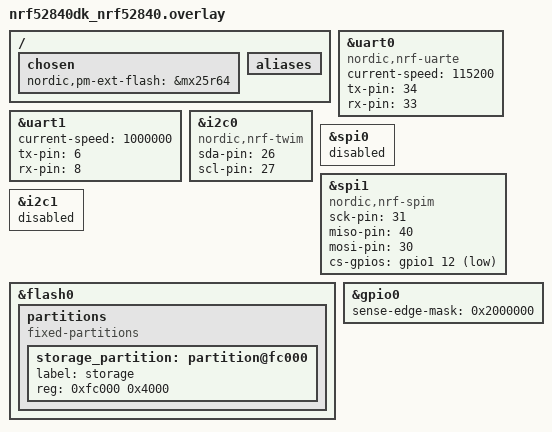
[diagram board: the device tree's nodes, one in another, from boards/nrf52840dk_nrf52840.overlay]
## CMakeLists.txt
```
# SPDX-License-Identifier: Apache-2.0

cmake_minimum_required(VERSION 3.13.1)

find_package(Zephyr REQUIRED HINTS $ENV{ZEPHYR_BASE})
project(comprensive_example)

# NORDIC SDK APP START

target_sources(app PRIVATE src/main.c)

target_sources_ifdef(CONFIG_EXAMPLE_I2C app
                     PRIVATE src/iic_thread.c)
					 
target_sources_ifdef(CONFIG_EXAMPLE_SPIM app
                     PRIVATE src/spi_thread.c)
					 
target_sources_ifdef(CONFIG_EXAMPLE_HS_UART app
                     PRIVATE src/uart_thread.c)
					 
target_sources_ifdef(CONFIG_EXAMPLE_ADC app
                     PRIVATE src/adc_thread.c)
					 
target_sources_ifdef(CONFIG_EXAMPLE_FLASH app
                     PRIVATE src/flash_thread.c)

zephyr_library_include_directories(.)

# NORDIC SDK APP END
```

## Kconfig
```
#
# Copyright (c) 2018 Nordic Semiconductor ASA
#
# SPDX-License-Identifier: LicenseRef-BSD-5-Clause-Nordic
#

source "Kconfig.zephyr"
menu "comprehensive example"

config EXAMPLE_I2C
	bool "load I2C example or not"
	help
		if yes, load I2C example
		
config EXAMPLE_SPIM
	bool "load SPI master example or not"
	help
		if yes, load SPI master example		
		
config EXAMPLE_EXT_INT
	bool "load external IO interrupt example or not"
	help
		if yes, load external IO interrupt example

config EXAMPLE_ADC
	bool "load ADC example or not"
	help
		if yes, load ADC example		

config EXAMPLE_HS_UART
	bool "load high speed UART example or not"
	help
		if yes, load high speed UART example	  

config EXAMPLE_FLASH
	bool "load Flash access usage example"
	default n
	help
		if yes, load Flash access usage example
		
config BT_NUS_SECURITY_ENABLED
	bool "Enable security"
	default n
	select BT_SMP
	help
	  "Enable BLE security for the UART service"
		
module = COMPREHENSIVE_EXAMPLE_CONFIG
module-str = comprehensive example configurations
source "${ZEPHYR_BASE}/subsys/logging/Kconfig.template.log_config"

endmenu
```

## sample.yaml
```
sample:
  name: Comprehensive example
  description: secondary slot on external QSPI flash
tests:
  samples.bluetooth.peripheral_uart:
    build_only: true
    build_on_all: true
    platform_allow: nrf51dk_nrf51422 nrf52dk_nrf52832 nrf52840dk_nrf52840
      nrf5340dk_nrf5340_cpuapp nrf5340dk_nrf5340_cpuappns
    tags: bluetooth ci_build
```

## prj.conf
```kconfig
CONFIG_NFCT_PINS_AS_GPIOS=y

## thread monitor ##
CONFIG_THREAD_ANALYZER=y
CONFIG_THREAD_NAME=y

## logging configurations ##
CONFIG_ASSERT=y
CONFIG_LOG=y
CONFIG_LOG_PRINTK=y
CONFIG_LOG_BUFFER_SIZE=8192

## Change logging backend to RTT ##
# CONFIG_LOG_BACKEND_UART=n
# CONFIG_LOG_BACKEND_RTT=y
# CONFIG_USE_SEGGER_RTT=y
# CONFIG_RTT_CONSOLE=y
# CONFIG_UART_CONSOLE=n

## peripherals ##
CONFIG_GPIO=y
CONFIG_DK_LIBRARY=y

## stack size configurations ##
CONFIG_SYSTEM_WORKQUEUE_STACK_SIZE=4096
# CONFIG_ISR_STACK_SIZE=2048
CONFIG_HEAP_MEM_POOL_SIZE=12288
CONFIG_MAIN_STACK_SIZE=2048

## I2C master example ##
CONFIG_EXAMPLE_I2C=y
CONFIG_I2C=y
CONFIG_NRFX_TWIM2=y

## external interrupt example (in IIC thread) ##
CONFIG_EXAMPLE_EXT_INT=y

## high speed uart example ##
CONFIG_EXAMPLE_HS_UART=y
CONFIG_SERIAL=y
CONFIG_UART_ASYNC_API=y
CONFIG_UART_1_ASYNC=y
CONFIG_NRFX_UARTE1=y
CONFIG_UART_1_NRF_HW_ASYNC=y
CONFIG_UART_1_NRF_HW_ASYNC_TIMER=1

## SPI master example ##
CONFIG_EXAMPLE_SPIM=y
CONFIG_SPI=y
CONFIG_NRFX_SPIM3=y

## Load ADC example ##
CONFIG_EXAMPLE_ADC=y
CONFIG_ADC=y
CONFIG_ADC_ASYNC=y
CONFIG_ADC_NRFX_SAADC=y

## Flash access usage example ##
CONFIG_EXAMPLE_FLASH=y
CONFIG_FLASH=y
CONFIG_FLASH_PAGE_LAYOUT=y
CONFIG_FLASH_MAP=y
CONFIG_NVS=y
CONFIG_MPU_ALLOW_FLASH_WRITE=y
CONFIG_SETTINGS=y

## Device power management example ##
CONFIG_PM_DEVICE=y

## BT configurations ##
CONFIG_BT=y
CONFIG_BT_PERIPHERAL=y
CONFIG_BT_DEVICE_NAME="comprehensive"
CONFIG_BT_L2CAP_TX_MTU=498
CONFIG_BT_BUF_ACL_RX_SIZE=502
CONFIG_BT_BUF_ACL_TX_SIZE=502
CONFIG_BT_CTLR_DATA_LENGTH_MAX=251
CONFIG_BT_MAX_CONN=2

# Enable the NUS service
CONFIG_BT_NUS=y

## Enable bonding ##
# CONFIG_BT_SETTINGS=y
# CONFIG_BT_L2CAP_DYNAMIC_CHANNEL=y
# CONFIG_BT_SETTINGS_CCC_STORE_ON_WRITE=y
# CONFIG_BT_NUS_SECURITY_ENABLED=y
# CONFIG_BT_SMP_ALLOW_UNAUTH_OVERWRITE=y
# # CONFIG_BT_USE_DEBUG_KEYS=y
# # CONFIG_BT_STORE_DEBUG_KEYS=y

## Open the following configs to run nrf_dfu ##
# CONFIG_NRF_DFU=y
# CONFIG_NRF_DFU_BT=y
# CONFIG_BOOTLOADER_MCUBOOT=y
# CONFIG_IMG_MANAGER=y
# CONFIG_MCUBOOT_IMG_MANAGER=y
# CONFIG_IMG_BLOCK_BUF_SIZE=4096
# CONFIG_BT_RX_STACK_SIZE=4096

## secondary slot on external Flash ##
CONFIG_PM_PARTITION_SIZE_SETTINGS_STORAGE=0x4000
CONFIG_NORDIC_QSPI_NOR=y
CONFIG_NORDIC_QSPI_NOR_FLASH_LAYOUT_PAGE_SIZE=4096
CONFIG_NORDIC_QSPI_NOR_STACK_WRITE_BUFFER_SIZE=16
CONFIG_STREAM_FLASH=y
CONFIG_STREAM_FLASH_ERASE=y

## Open the following configs to run SMP DFU ##
CONFIG_BOOTLOADER_MCUBOOT=y
CONFIG_MCUMGR=y
CONFIG_MCUMGR_SMP_BT=y
CONFIG_MCUMGR_SMP_BT_AUTHEN=n
CONFIG_MCUMGR_CMD_IMG_MGMT=y
CONFIG_MCUMGR_CMD_OS_MGMT=y
CONFIG_OS_MGMT_TASKSTAT=n
CONFIG_OS_MGMT_ECHO=y
CONFIG_IMG_BLOCK_BUF_SIZE=2048
CONFIG_MCUMGR_SMP_REASSEMBLY_BT=y
CONFIG_MCUMGR_BUF_SIZE=2475
CONFIG_OS_MGMT_MCUMGR_PARAMS=y
CONFIG_MCUMGR_SMP_BT_CONN_PARAM_CONTROL=y
# Enable the storage erase command.
CONFIG_MCUMGR_GRP_ZEPHYR_BASIC=y
CONFIG_MCUMGR_GRP_BASIC_CMD_STORAGE_ERASE=y
```

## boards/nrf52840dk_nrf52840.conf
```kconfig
## Change logging backend to RTT ##
CONFIG_LOG_BACKEND_UART=n
CONFIG_LOG_BACKEND_RTT=y
CONFIG_USE_SEGGER_RTT=y
CONFIG_RTT_CONSOLE=y
CONFIG_UART_CONSOLE=n
CONFIG_NRFX_TWIM0=y
CONFIG_NRFX_TWIM2=n
```

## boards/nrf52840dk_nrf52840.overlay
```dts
/* Open this config for NCS v1.8.0 or newer */
/ {
	chosen {
		nordic,pm-ext-flash = &mx25r64;
	};
};

&uart0 {
	compatible = "nordic,nrf-uarte";
	status = "okay";
	current-speed = < 115200 >;
	tx-pin = < 34 >;
	rx-pin = < 33 >;
	/* delete rts-pin&cts-pin to release the related 2 pins for other uses */
	/delete-property/ rts-pin;
	/delete-property/ cts-pin;
};

&uart1 {
	status = "okay";
	current-speed = < 1000000 >;
	tx-pin = < 6 >;
	rx-pin = < 8 >;
};

my_i2c: &i2c0 {
	status = "okay";
	compatible = "nordic,nrf-twim";
	sda-pin = <26>;
	scl-pin = <27>;
};

&spi0 {
	status = "disabled";
};

my_spi: &spi1 {
	status = "okay"; 
	compatible = "nordic,nrf-spim";
	sck-pin = < 31 >;
	miso-pin = < 40 >;
	mosi-pin = < 30 >;
	cs-gpios = <&gpio1 12 GPIO_ACTIVE_LOW>;
};

&i2c1 {
	status = "disabled";
};

/* delete sw3 to reserve the related pin for GPIO use */
/ {
	aliases {  
	 /delete-property/ sw3;
	};
   };

/delete-node/ &storage_partition;
&flash0{
		partitions {
			compatible = "fixed-partitions";
			#address-cells = < 0x1 >;
			#size-cells = < 0x1 >;

			storage_partition: partition@fc000 {
				label = "storage";
				reg = < 0xfc000 0x4000 >;
			};
		};
};

&gpio0 {
	/* pin 0x19 sense for edge */
	sense-edge-mask = <0x2000000>;
};
```

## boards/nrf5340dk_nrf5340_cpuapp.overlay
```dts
/* overlay file for app core */

/* Open this config for NCS v1.8.0 or newer */
/ {
	chosen {
		nordic,pm-ext-flash = &mx25r64;
	};
};

&uart0 {
	compatible = "nordic,nrf-uarte";
	status = "okay";
	current-speed = < 115200 >;	
	tx-pin = < 0x14 >;
	rx-pin = < 0x16 >;
	/* delete rts-pin&cts-pin to release the related 2 pins for other uses */
	/delete-property/ rts-pin;
	/delete-property/ cts-pin;
};

&uart1 {
	status = "okay";
	current-speed = < 1000000 >;
	tx-pin = < 26 >;
	rx-pin = < 7 >;
};

&i2c1 {
	status = "disabled";
};

my_i2c: &i2c2 {
	status = "okay";
	compatible = "nordic,nrf-twim";
	sda-pin = <4>;
	scl-pin = <27>;
};

&spi2 {
	status = "disabled";
};

my_spi: &spi3 {
	status = "okay"; 
	compatible = "nordic,nrf-spim";
	sck-pin = < 47 >;
	miso-pin = < 46 >;
	mosi-pin = < 45 >;
	cs-gpios = <&gpio1 12 GPIO_ACTIVE_LOW>;
};

/* delete sw3 to reserve the related pin for GPIO use */
/ {
	aliases {  
	 /delete-property/ sw3;
	};
  };

/delete-node/ &storage_partition;
&flash0{
		partitions {
			compatible = "fixed-partitions";
			#address-cells = < 0x1 >;
			#size-cells = < 0x1 >;

			storage_partition: partition@fc000 {
				label = "storage";
				reg = < 0xfc000 0x4000 >;
			};
		};
};

&gpio0 {
	/* pin9 sense for edge */
	sense-edge-mask = <0x200>;
};
```

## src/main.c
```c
/*
 * Copyright (c) 2020 Nordic Semiconductor ASA
 *
 * SPDX-License-Identifier: LicenseRef-BSD-5-Clause-Nordic
 */

#include <zephyr.h>
#include <device.h>
#include <devicetree.h>
#include <drivers/gpio.h>
#include <stdio.h>
#include <dk_buttons_and_leds.h>
#include <nrf.h>
#include <nrfx.h>
#include <drivers/uart.h>
#include <bluetooth/bluetooth.h>
#include <bluetooth/uuid.h>
#include <bluetooth/gatt.h>
#include <bluetooth/hci.h>
#include <bluetooth/services/nus.h>
#include <settings/settings.h>

#ifdef CONFIG_MCUMGR
#include "img_mgmt/img_mgmt.h"
#include "os_mgmt/os_mgmt.h"
#include <img_mgmt/img_mgmt_impl.h>
#include <mgmt/mcumgr/smp_bt.h>
#endif

#ifdef CONFIG_NRF_DFU
#include "nrf_dfu_settings.h"
#include "nrf_dfu.h"
#include "sys/reboot.h"
#include "nrf_dfu.h"
#include "nrf_dfu_validation.h"
#endif
#include <logging/log.h>
#include <logging/log_ctrl.h>
#include <pm/device.h>

#define LOG_MODULE_NAME main
LOG_MODULE_REGISTER(LOG_MODULE_NAME);

#define DEVICE_NAME CONFIG_BT_DEVICE_NAME
#define DEVICE_NAME_LEN	(sizeof(DEVICE_NAME) - 1)
#define KEY_PASSKEY_ACCEPT DK_BTN1_MSK
#define KEY_PASSKEY_REJECT DK_BTN2_MSK

#define ERASE_DELAY_AFTER_BOOT 30   //unit: s
static struct k_work_delayable blinky_work;
K_SEM_DEFINE(sem_spi_txrx, 0, 1);

static struct bt_conn *current_conn;
static struct bt_conn *auth_conn;
const struct device *runLED;
const struct device *conLED;
bool led_is_on = true;

static const struct bt_data ad[] = {
	BT_DATA_BYTES(BT_DATA_FLAGS, (BT_LE_AD_GENERAL | BT_LE_AD_NO_BREDR)),
	BT_DATA(BT_DATA_NAME_COMPLETE, DEVICE_NAME, DEVICE_NAME_LEN),
};

static const struct bt_data sd[] = {
	BT_DATA_BYTES(BT_DATA_UUID128_ALL, BT_UUID_NUS_VAL),
};

/* Stack definition for application workqueue */
K_THREAD_STACK_DEFINE(application_stack_area,
		      1024);
static struct k_work_q application_work_q;

#define LED0_NODE DT_ALIAS(led0)
#define LED0	DT_GPIO_LABEL(LED0_NODE, gpios)
#define LED0_PIN	DT_GPIO_PIN(LED0_NODE, gpios)
#define LED0_FLAGS	DT_GPIO_FLAGS(LED0_NODE, gpios)

#define LED1_NODE DT_ALIAS(led1)
#define LED1	DT_GPIO_LABEL(LED1_NODE, gpios)
#define LED1_PIN	DT_GPIO_PIN(LED1_NODE, gpios)
#define LED1_FLAGS	DT_GPIO_FLAGS(LED1_NODE, gpios)

#ifdef CONFIG_PM_DEVICE
const struct device *devUart0;
const struct device *devUart1;
static void get_device_handles(void)
{
	devUart0 = device_get_binding("UART_0");
    devUart1 = device_get_binding("UART_1");
}

void set_device_pm_state(void)
{
	int err;
	enum pm_device_state pm_state;

	if (devUart1)
	{
		pm_device_state_get(devUart1, &pm_state);
		if (pm_state == PM_DEVICE_STATE_SUSPENDED)
		{
			LOG_INF("UART1 is in low power state. We activate it");
			err = pm_device_action_run(devUart1,PM_DEVICE_ACTION_RESUME);
			if (err) {
				LOG_ERR("UART1 enable failed");			
			}
			else
			{
				LOG_INF("## UART1 is active now ##");
			}		
		}
		else if (pm_state == PM_DEVICE_STATE_ACTIVE)
		{
			LOG_INF("UART1 is in active state. We suspend it");

#if CONFIG_UART_ASYNC_API && CONFIG_UART_1_NRF_HW_ASYNC
		((const struct uart_driver_api *)devUart1->api)->rx_disable(devUart1);
#endif			
			err = pm_device_action_run(devUart1,	PM_DEVICE_ACTION_SUSPEND);
			if (err) {
				LOG_ERR("UART1 disable failed");
			}
			else
			{
				LOG_INF("## UART1 is suspended now ##");
			}		
		}
	}

	pm_device_state_get(devUart0, &pm_state);
	if (pm_state == PM_DEVICE_STATE_SUSPENDED)
	{
		LOG_INF("UART0 is in low power state. We activate it");
		err = pm_device_action_run(devUart0,	PM_DEVICE_ACTION_RESUME);
		if (err) {
			LOG_ERR("UART0 enable failed");			
		}
		else
		{
			LOG_INF("## UART0 is active now ##");
		}		
	}
	else if (pm_state == PM_DEVICE_STATE_ACTIVE)
	{
		LOG_INF("UART0 is in active state. We suspend it");
		//print out all the pending logging messages
		while(log_process(false));

#if CONFIG_UART_ASYNC_API && CONFIG_UART_0_NRF_HW_ASYNC
		((const struct uart_driver_api *)devUart0->api)->rx_disable(devUart0);
#endif
		err = pm_device_action_run(devUart0,	PM_DEVICE_ACTION_SUSPEND);
		if (err) {
			LOG_ERR("UART0 disable failed");
		}
		else
		{
			LOG_INF("## UART0 is suspended now ##");
		}		
	}

}
#endif //CONFIG_PM_DEVICE

static void blinky_work_fn(struct k_work *work)
{
    //LOG_INF("blinky fn in system workqueue\n");
	gpio_pin_set(runLED, LED0_PIN, (int)led_is_on);
	led_is_on = !led_is_on;

	k_work_reschedule_for_queue(&application_work_q, &blinky_work,
					   	K_SECONDS(2));

}

#ifdef CONFIG_NRF_DFU

/**@brief Function for handling DFU events.
 */
static void dfu_observer(nrf_dfu_evt_type_t evt_type)
{
    switch (evt_type)
    {
        case NRF_DFU_EVT_DFU_STARTED:
        case NRF_DFU_EVT_OBJECT_RECEIVED:

            break;
        case NRF_DFU_EVT_DFU_COMPLETED:
        case NRF_DFU_EVT_DFU_ABORTED:
			LOG_INF("resetting...");
			while(log_process(false));
            sys_reboot(SYS_REBOOT_WARM);
            break;
        case NRF_DFU_EVT_TRANSPORT_DEACTIVATED:
            // Reset the internal state of the DFU settings to the last stored state.
			LOG_INF("NRF_DFU_EVT_TRANSPORT_DEACTIVATED");
            nrf_dfu_settings_reinit();
            break;
        default:
            break;
    }

}

int dfu_init(void)
{
    int ret_val;

    ret_val = nrf_dfu_settings_init(true);
    if (ret_val != NRF_SUCCESS)
	{
		LOG_WRN("dfu settings init err %d", ret_val);
	}

    ret_val = nrf_dfu_init(dfu_observer);
    if (ret_val != NRF_SUCCESS)
	{
		LOG_WRN("dfu init err %d", ret_val);
	}

    return ret_val;
}
#endif //CONFIG_NRF_DFU

#ifdef CONFIG_BT_GATT_CLIENT
static struct bt_gatt_exchange_params exchange_params;

static void exchange_func(struct bt_conn *conn, uint8_t att_err,
			  struct bt_gatt_exchange_params *params)
{
	if (att_err)
	{
		LOG_ERR("MTU exchange failed");
	}
	else
	{
		LOG_INF("MTU updated to %d", bt_gatt_get_mtu(conn)); 
	}
	
}
#endif

static void connected(struct bt_conn *conn, uint8_t err)
{
	char addr[BT_ADDR_LE_STR_LEN];

	if (err) {
		LOG_ERR("Connection failed (err %u)", err);
		return;
	}

	bt_addr_le_to_str(bt_conn_get_dst(conn), addr, sizeof(addr));
	LOG_INF("Connected %s", log_strdup(addr));

	current_conn = bt_conn_ref(conn);

#ifdef CONFIG_BT_NUS_SECURITY_ENABLED
	if (bt_conn_set_security(conn, BT_SECURITY_L3)) {
		LOG_INF("Failed to set security\n");
	}	
#endif
#ifdef CONFIG_BT_GATT_CLIENT		
	exchange_params.func = exchange_func;
	err = bt_gatt_exchange_mtu(conn, &exchange_params);
	if (err) {
		LOG_ERR("MTU exchange failed");
	} 		
#endif

	gpio_pin_set(conLED, LED1_PIN, 1);
}

static void disconnected(struct bt_conn *conn, uint8_t reason)
{
	char addr[BT_ADDR_LE_STR_LEN];

	bt_addr_le_to_str(bt_conn_get_dst(conn), addr, sizeof(addr));

	LOG_INF("Disconnected: %s (reason %u)", log_strdup(addr), reason);

	if (auth_conn) {
		bt_conn_unref(auth_conn);
		auth_conn = NULL;
	}

	if (current_conn) {
		bt_conn_unref(current_conn);
		current_conn = NULL;
		gpio_pin_set(conLED, LED1_PIN, 0);
	}
}

#ifdef CONFIG_BT_NUS_SECURITY_ENABLED
static void security_changed(struct bt_conn *conn, bt_security_t level,
			     enum bt_security_err err)
{
	char addr[BT_ADDR_LE_STR_LEN];

	bt_addr_le_to_str(bt_conn_get_dst(conn), addr, sizeof(addr));

	if (!err) {
		LOG_INF("Security changed: %s level %u", log_strdup(addr),
			level);
	} else {
		LOG_WRN("Security failed: %s level %u err %d", log_strdup(addr),
			level, err);
	}
}
#endif

static void param_updated(struct bt_conn *conn, uint16_t interval,
				 uint16_t latency, uint16_t timeout)
{
	LOG_INF("conn interval=%d, latency=%d, timeout=%d", interval, latency, timeout);
}
static struct bt_conn_cb conn_callbacks = {
	.connected    = connected,
	.disconnected = disconnected,
	.le_param_updated = param_updated,
#ifdef CONFIG_BT_NUS_SECURITY_ENABLED
	.security_changed = security_changed,
#endif
};

#if defined(CONFIG_BT_NUS_SECURITY_ENABLED)
static void auth_passkey_display(struct bt_conn *conn, unsigned int passkey)
{
	char addr[BT_ADDR_LE_STR_LEN];

	bt_addr_le_to_str(bt_conn_get_dst(conn), addr, sizeof(addr));

	LOG_INF("Passkey for %s: %06u", log_strdup(addr), passkey);
}

static void auth_passkey_confirm(struct bt_conn *conn, unsigned int passkey)
{
	char addr[BT_ADDR_LE_STR_LEN];

	auth_conn = bt_conn_ref(conn);

	bt_addr_le_to_str(bt_conn_get_dst(conn), addr, sizeof(addr));

	LOG_INF("Passkey for %s: %06u", log_strdup(addr), passkey);
	LOG_INF("Press Button 1 to confirm, Button 2 to reject.");
}


static void auth_cancel(struct bt_conn *conn)
{
	char addr[BT_ADDR_LE_STR_LEN];

	bt_addr_le_to_str(bt_conn_get_dst(conn), addr, sizeof(addr));

	LOG_INF("Pairing cancelled: %s", log_strdup(addr));
}

static void pairing_complete(struct bt_conn *conn, bool bonded)
{
	char addr[BT_ADDR_LE_STR_LEN];

	bt_addr_le_to_str(bt_conn_get_dst(conn), addr, sizeof(addr));

	LOG_INF("Pairing completed: %s, bonded: %d", log_strdup(addr),
		bonded);
}


static void pairing_failed(struct bt_conn *conn, enum bt_security_err reason)
{
	char addr[BT_ADDR_LE_STR_LEN];

	bt_addr_le_to_str(bt_conn_get_dst(conn), addr, sizeof(addr));

	LOG_INF("Pairing failed conn: %s, reason %d", log_strdup(addr),
		reason);
}


static struct bt_conn_auth_cb conn_auth_callbacks = {
	.passkey_display = auth_passkey_display,
	.passkey_confirm = auth_passkey_confirm,
	.cancel = auth_cancel,	
	.pairing_complete = pairing_complete,
	.pairing_failed = pairing_failed
};
#else
static struct bt_conn_auth_cb conn_auth_callbacks;
#endif

extern int my_uart_send(const uint8_t *buf, size_t len);
static void bt_receive_cb(struct bt_conn *conn, const uint8_t *const data,
			  uint16_t len)
{
	int err;
	char addr[BT_ADDR_LE_STR_LEN] = {0};

	bt_addr_le_to_str(bt_conn_get_dst(conn), addr, ARRAY_SIZE(addr));

	LOG_INF("Received data from: %s", log_strdup(addr));

	err = my_uart_send(data, len);
	
}

static struct bt_nus_cb nus_cb = {
	.received = bt_receive_cb,
};

void error(void)
{
	dk_set_leds_state(DK_ALL_LEDS_MSK, DK_NO_LEDS_MSK);

	while (true) {
		/* Spin for ever */
		k_sleep(K_MSEC(1000));
	}
}
#if defined(CONFIG_BT_NUS_SECURITY_ENABLED)
static void num_comp_reply(bool accept)
{
	if (accept) {
		bt_conn_auth_passkey_confirm(auth_conn);
		LOG_INF("Numeric Match, conn %p", (void *)auth_conn);
	} else {
		bt_conn_auth_cancel(auth_conn);
		LOG_INF("Numeric Reject, conn %p", (void *)auth_conn);
	}

	bt_conn_unref(auth_conn);
	auth_conn = NULL;
}
#endif

void button_changed(uint32_t button_state, uint32_t has_changed)
{
	uint32_t buttons = button_state & has_changed;

	if (buttons & DK_BTN2_MSK) {
		LOG_INF("button2 isr");
		k_sem_give(&sem_spi_txrx);
	}

	if (buttons & DK_BTN3_MSK) {
		LOG_INF("button3 isr");
#ifdef CONFIG_PM_DEVICE		
		set_device_pm_state();
#endif		
	}

#if defined(CONFIG_BT_NUS_SECURITY_ENABLED)
	if (auth_conn) {
		if (buttons & KEY_PASSKEY_ACCEPT) {
			num_comp_reply(true);
		}

		if (buttons & KEY_PASSKEY_REJECT) {
			num_comp_reply(false);
		}
	}
#endif

}

void main(void)
{
	int err;	

	LOG_INF("### comprehensive example v0.4 compiled at %s %s\n", __TIME__, __DATE__);

	runLED = device_get_binding(LED0);
	if (runLED == NULL) {
		LOG_ERR("LED0 bind null\n");
	}
	err = gpio_pin_configure(runLED, LED0_PIN, GPIO_OUTPUT_ACTIVE | LED0_FLAGS);
	if (err < 0) {
		LOG_ERR("led0 configure error %d \n", err);		
	}

	conLED = device_get_binding(LED1);
	if (conLED == NULL) {
		LOG_ERR("LED1 bind null\n");
	}
	err = gpio_pin_configure(conLED, LED1_PIN, GPIO_OUTPUT_ACTIVE | LED1_FLAGS);
	if (err < 0) {
		LOG_ERR("led1 configure error %d \n", err);		
	}
	gpio_pin_set(conLED, LED1_PIN, 0);	

	//only initialize buttons module. LED moudle is not used!
	err = dk_buttons_init(button_changed);
	if (err) {
		LOG_ERR("Cannot init buttons (err: %d)", err);
	}

#ifdef CONFIG_PM_DEVICE
	get_device_handles();
#endif

	k_work_queue_start(&application_work_q, application_stack_area,
			   K_THREAD_STACK_SIZEOF(application_stack_area), 10,
			   NULL);
	k_work_init_delayable(&blinky_work, blinky_work_fn);
	k_work_reschedule_for_queue(&application_work_q, &blinky_work,
					   	K_MSEC(20));	

	bt_conn_cb_register(&conn_callbacks);

	if (IS_ENABLED(CONFIG_BT_NUS_SECURITY_ENABLED)) {
		bt_conn_auth_cb_register(&conn_auth_callbacks);
	}

	err = bt_enable(NULL);
	if (err) {
		error();
	}

	LOG_INF("Bluetooth initialized");

	if (IS_ENABLED(CONFIG_SETTINGS)) {
		settings_load();
	}

	err = bt_nus_init(&nus_cb);
	if (err) {
		LOG_ERR("Failed to initialize UART service (err: %d)", err);
		return;
	}

#ifdef CONFIG_MCUMGR
	smp_bt_register();
	os_mgmt_register_group();
	img_mgmt_register_group();
#endif

#ifdef CONFIG_NRF_DFU
	err = dfu_init();
	if (err) {
		LOG_ERR("dfu service init err %d", err);		
	}
#endif //CONFIG_NRF_DFU

	err = bt_le_adv_start(BT_LE_ADV_CONN, ad, ARRAY_SIZE(ad), sd,
			      ARRAY_SIZE(sd));
	if (err) {
		LOG_ERR("Advertising failed to start (err %d)", err);
	}

	while(1)
	{
		//add your code here
		k_sleep(K_SECONDS(20));
		LOG_INF("main thread\n");
	}

}
```

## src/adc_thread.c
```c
/*
 * Copyright (c) 2020 Nordic Semiconductor ASA
 *
 * SPDX-License-Identifier: LicenseRef-BSD-5-Clause-Nordic
 */

#include <zephyr.h>
#include <device.h>
#include <devicetree.h>
#include <drivers/gpio.h>
#include <logging/log.h>
#include <drivers/adc.h>
#include <hal/nrf_saadc.h>

LOG_MODULE_REGISTER(adc_thread, 3);

#define NUM_OF_CH 2
#define ADC_DEVICE_NAME		DT_LABEL(DT_NODELABEL(adc))
#define ADC_RESOLUTION		12
#define ADC_OVERSAMPLING	4 /* 2^ADC_OVERSAMPLING samples are averaged */
#define ADC_MAX 		4096
#define BATTERY_MEAS_VOLTAGE_GAIN	6
#define ADC_GAIN		ADC_GAIN_1_6
#define ADC_REFERENCE		ADC_REF_INTERNAL
#define ADC_REF_INTERNAL_MV	600UL
#define ADC_ACQUISITION_TIME	ADC_ACQ_TIME(ADC_ACQ_TIME_MICROSECONDS, 10)
#define ADC_CHANNEL_ID		0
#define ADC_CHANNEL_INPUT	NRF_SAADC_INPUT_VDD
#define ADC_CHANNEL_ID2		1
#define ADC_CHANNEL_INPUT2	NRF_SAADC_INPUT_AIN1   //P0.05
/* ADC asynchronous read is scheduled on odd works. Value read happens during
 * even works. This is done to avoid creating a thread for battery monitor.
 */
#define ADC_SAMPLE_INTERVAL	20  //unit:s

#define BATTERY_VOLTAGE(sample) (sample * BATTERY_MEAS_VOLTAGE_GAIN	\
				 * ADC_REF_INTERNAL_MV / ADC_MAX)


static const struct device *adc_dev;
static int16_t adc_buffer[NUM_OF_CH];
static bool adc_async_read_pending;

#ifndef CONFIG_NCS_V1_5_x
static struct k_work_delayable adc_work;
#else
static struct k_delayed_work adc_work;
#endif

static struct k_poll_signal async_sig = K_POLL_SIGNAL_INITIALIZER(async_sig);
static struct k_poll_event  async_evt =
	K_POLL_EVENT_INITIALIZER(K_POLL_TYPE_SIGNAL,
				 K_POLL_MODE_NOTIFY_ONLY,
				 &async_sig);

static struct adc_sequence sequence = {
	.options	= NULL,
	.channels	= BIT(ADC_CHANNEL_ID),
	.buffer		= adc_buffer,
	.buffer_size	= sizeof(adc_buffer),
	.resolution	= ADC_RESOLUTION,
	.oversampling	= ADC_OVERSAMPLING,
	.calibrate	= false,
};
static struct adc_sequence sequence_calibrate = {
	.options	= NULL,
	.channels	= BIT(ADC_CHANNEL_ID),
	.buffer		= adc_buffer,
	.buffer_size	= sizeof(adc_buffer),
	.resolution	= ADC_RESOLUTION,
	.oversampling	= ADC_OVERSAMPLING,
	.calibrate	= true,
};

static bool calibrated;

void adc_sample_sync(void)
{
	int err;

	if (NUM_OF_CH == 2)
	{
		sequence.channels = BIT(ADC_CHANNEL_ID) | BIT(ADC_CHANNEL_ID2);
		sequence_calibrate.channels = BIT(ADC_CHANNEL_ID) | BIT(ADC_CHANNEL_ID2);
		sequence.oversampling  = NRF_SAADC_OVERSAMPLE_DISABLED;
		sequence_calibrate.oversampling  = NRF_SAADC_OVERSAMPLE_DISABLED;
	}
	if (likely(calibrated)) {		
		err = adc_read(adc_dev, &sequence);
	} else {
		err = adc_read(adc_dev, &sequence_calibrate);
		calibrated = true;
	}
	if (err) {
		LOG_WRN("ADC read err %d", err);
	} else {
		for (int i = 0; i < NUM_OF_CH; i++)
		{
			uint32_t voltage = BATTERY_VOLTAGE(adc_buffer[i]);
			LOG_INF("Voltage%d: %u mV / %d", i, voltage, adc_buffer[i]);
		}
	}			
}
#ifdef CONFIG_ADC_ASYNC
static void adc_sample_async(struct k_work *work)
{
	int err;

	if (NUM_OF_CH == 2)
	{
		sequence.channels = BIT(ADC_CHANNEL_ID) | BIT(ADC_CHANNEL_ID2);
		sequence_calibrate.channels = BIT(ADC_CHANNEL_ID) | BIT(ADC_CHANNEL_ID2);
		sequence.oversampling  = NRF_SAADC_OVERSAMPLE_DISABLED;
		sequence_calibrate.oversampling  = NRF_SAADC_OVERSAMPLE_DISABLED;		
	}
	if (!adc_async_read_pending) {
		if (likely(calibrated)) {
			err = adc_read_async(adc_dev, &sequence, &async_sig);
		} else {
			err = adc_read_async(adc_dev, &sequence_calibrate,
					     &async_sig);
			calibrated = true;
		}

		if (err) {
			LOG_WRN("adc_read_async err %d", err);
		} else {
			adc_async_read_pending = true;
		}
	} else {
		err = k_poll(&async_evt, 1, K_NO_WAIT);
		if (err) {
			LOG_WRN("ADC sampling timeout");
		} else {
			adc_async_read_pending = false;			
			for (int i = 0; i < NUM_OF_CH; i++)
			{
				uint32_t voltage = BATTERY_VOLTAGE(adc_buffer[i]);
				LOG_INF("Voltage%d: %u mV / %d async", i, voltage, adc_buffer[i]);
			}			
		}
	}
#ifndef CONFIG_NCS_V1_5_x
	k_work_reschedule(&adc_work, K_SECONDS(ADC_SAMPLE_INTERVAL));
#else
	k_delayed_work_submit(&adc_work, K_SECONDS(ADC_SAMPLE_INTERVAL));
#endif	

}
#endif

static int init_adc(void)
{
	int err;

	adc_dev = device_get_binding(ADC_DEVICE_NAME);
	if (!adc_dev) {
		LOG_ERR("Cannot get ADC device");
		return -ENXIO;
	}

	struct adc_channel_cfg channel_cfg = {
		.gain             = ADC_GAIN,
		.reference        = ADC_REFERENCE,
		.acquisition_time = ADC_ACQUISITION_TIME,
		.channel_id       = ADC_CHANNEL_ID,
		.differential	  = 0,
#if defined(CONFIG_ADC_CONFIGURABLE_INPUTS)
		.input_positive   = ADC_CHANNEL_INPUT,
#endif
	};
	err = adc_channel_setup(adc_dev, &channel_cfg);
	if (err) {
		LOG_ERR("Setting up the ADC channel%d failed", ADC_CHANNEL_ID);
		return err;
	}

	if (NUM_OF_CH == 2)
	{
		channel_cfg.channel_id = ADC_CHANNEL_ID2;
		channel_cfg.input_positive = ADC_CHANNEL_INPUT2;
		err = adc_channel_setup(adc_dev, &channel_cfg);
		if (err) {
			LOG_ERR("Setting up the ADC channel%d failed", ADC_CHANNEL_ID2);
			return err;
		}		
	}


#ifdef CONFIG_ADC_ASYNC
#ifndef CONFIG_NCS_V1_5_x
	k_work_init_delayable(&adc_work, adc_sample_async);
	k_work_reschedule(&adc_work, K_MSEC(10));
#else
	k_delayed_work_init(&adc_work, adc_sample_async);
	k_delayed_work_submit(&adc_work, K_MSEC(10));
#endif //CONFIG_NCS_V1_5_x	
#endif //CONFIG_ADC_ASYNC

	return 0;
}


void adc_thread(void)
{	
	
	LOG_INF("**ADC sampling example");
	init_adc();

	while (1) {                
        LOG_INF("ADC thread");
        adc_sample_sync();
        k_sleep(K_SECONDS(ADC_SAMPLE_INTERVAL)); 
	}
}

K_THREAD_DEFINE(adc_thread_id, 1024, adc_thread, NULL, NULL,
		NULL, 8, 0, 0);
```

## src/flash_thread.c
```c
/*
 * Copyright (c) 2020 Nordic Semiconductor ASA
 *
 * SPDX-License-Identifier: LicenseRef-BSD-5-Clause-Nordic
 */

#include <zephyr.h>
#include <power/reboot.h>
#include <device.h>
#include <string.h>
#include <drivers/flash.h>
#include <storage/flash_map.h>
#include <fs/nvs.h>
#include "settings/settings.h"
#include <logging/log.h>

#define LOG_MODULE_NAME flash_thread
LOG_MODULE_REGISTER(LOG_MODULE_NAME);

static struct nvs_fs fs;

#define KEY_ID 1
#define RBT_CNT_ID 2

int nvs_usage_init(void)
{
	int rc;
	uint8_t key[8];
	uint32_t reboot_counter = 0U;
	const struct device *flash_dev;
	struct flash_pages_info info;

	flash_dev = device_get_binding(DT_CHOSEN_ZEPHYR_FLASH_CONTROLLER_LABEL);
	if (!device_is_ready(flash_dev)) {
		LOG_ERR("Flash device %s is not ready", flash_dev->name);
		return -EINVAL;
	}
	fs.offset = FLASH_AREA_OFFSET(storage);
	rc = flash_get_page_info_by_offs(flash_dev, fs.offset, &info);
	if (rc) {
		LOG_ERR("Unable to get page info");
		return -EINVAL;
	}
	fs.sector_size = info.size;
	fs.sector_count = CONFIG_PM_PARTITION_SIZE_SETTINGS_STORAGE / info.size;

	LOG_INF("NVS sector size=%d sector count=%d\n", fs.sector_size, fs.sector_count);

	rc = nvs_init(&fs, DT_CHOSEN_ZEPHYR_FLASH_CONTROLLER_LABEL);
	if (rc)
	{
		LOG_ERR("Flash Init failed %d", rc);
		return -EINVAL;
	}

	/* KEY_ID is used to store a key, lets see if we can read it from flash
	 */
	rc = nvs_read(&fs, KEY_ID, &key, sizeof(key));
	if (rc > 0)
	{ /* item was found, show it */
		LOG_HEXDUMP_INF(key, sizeof(key), "Key value in NVS:");
	}
	else
	{ /* item was not found, add it */
		LOG_INF("No key found, adding it at id %d by NVS API", KEY_ID);
		key[0] = 0xFF;
		key[1] = 0xFE;
		key[2] = 0xFD;
		key[3] = 0xFC;
		key[4] = 0xFB;
		key[5] = 0xFA;
		key[6] = 0xF9;
		key[7] = 0xF8;
		(void)nvs_write(&fs, KEY_ID, &key, sizeof(key));
	}
	/* RBT_CNT_ID is used to store the reboot counter, lets see
	 * if we can read it from flash
	 */
	reboot_counter = 0;
	rc = nvs_read(&fs, RBT_CNT_ID, &reboot_counter, sizeof(reboot_counter));
	if (rc > 0)
	{ /* item was found, show it */
		LOG_INF("*** Reboot counter in NVS: %d ***",
				reboot_counter);
	}
	LOG_INF("save new reboot counter by NVS API");
	reboot_counter++;
	(void)nvs_write(&fs, RBT_CNT_ID, &reboot_counter,
					sizeof(reboot_counter));

	return 0;
}

static uint32_t reboot_cnt;
static uint8_t key_s[8];

int alpha_handle_set(const char *name, size_t len, settings_read_cb read_cb,
					 void *cb_arg)
{
	const char *next;
	int rc;

	LOG_INF("set handler name=%s, len=%d ", log_strdup(name), len);
	if (settings_name_steq(name, "boot_cnt", &next) && !next)
	{
		if (len != sizeof(reboot_cnt))
		{
			return -EINVAL;
		}
		rc = read_cb(cb_arg, &reboot_cnt, sizeof(reboot_cnt));
		LOG_INF("*** Reboot counter in Settings: %d ****", reboot_cnt);
		return 0;
	}

	if (settings_name_steq(name, "key", &next) && !next)
	{
		if (len != sizeof(key_s))
		{
			return -EINVAL;
		}
		rc = read_cb(cb_arg, key_s, sizeof(key_s));
		LOG_HEXDUMP_INF(key_s, sizeof(key_s), "Key value in Settings:");
		return 0;
	}

	return -ENOENT;
}

/* dynamic main tree handler */
struct settings_handler alph_handler = {
	.name = "alpha",
	.h_get = NULL,
	.h_set = alpha_handle_set,
	.h_commit = NULL,
	.h_export = NULL};

void settings_usage_init(void)
{
	int rc;

	rc = settings_subsys_init();
	if (rc)
	{
		LOG_ERR("settings subsys initialization: fail (err %d) ", rc);
		return;
	}

	LOG_INF("settings subsys initialization: OK.");

	rc = settings_register(&alph_handler);
	if (rc)
	{
		LOG_ERR("subtree <%s> handler registered: fail (err %d)",
				alph_handler.name, rc);
	}

	/* load all key-values at once
	 * In case a key-value doesn't exist in the storage
	 * default valuse should be assigned to settings variable
	 * before any settings load call
	 */
	LOG_INF("Load all key-value pairs using registered handlers");
	settings_load();

	if (reboot_cnt == 0)
	{
		LOG_INF("save key_s By Settings API");
		key_s[0] = 0x30;
		key_s[1] = 0x31;
		key_s[2] = 0x32;
		key_s[3] = 0x33;
		key_s[4] = 0x34;
		key_s[5] = 0x35;
		key_s[6] = 0x36;
		key_s[7] = 0x37;
		rc = settings_save_one("alpha/key", (const void *)key_s,
							   sizeof(key_s));
		if (rc)
		{
			LOG_ERR("key_s save err %d ", rc);
		}
	}

	LOG_INF("save new reboot counter by Settings API");
	reboot_cnt++;
	rc = settings_save_one("alpha/boot_cnt", (const void *)&reboot_cnt,
						   sizeof(reboot_cnt));
	if (rc)
	{
		LOG_ERR("boot_cnt save err %d ", rc);
	}
}
void flash_thread(void)
{

	LOG_INF("**Flash access example using both NVS and settings API");

	nvs_usage_init();

	settings_usage_init();

	while (1)
	{
		LOG_INF("Flash thread");
		k_sleep(K_SECONDS(20));
	}
}

K_THREAD_DEFINE(flash_thread_id, 1024, flash_thread, NULL, NULL,
				NULL, 9, 0, 0);
```

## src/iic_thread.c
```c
/*
 * Copyright (c) 2020 Nordic Semiconductor ASA
 *
 * SPDX-License-Identifier: LicenseRef-BSD-5-Clause-Nordic
 */

#include <zephyr.h>
#include <device.h>
#include <devicetree.h>
#include <drivers/gpio.h>
#include <drivers/i2c.h>
#include <logging/log.h>

#define LOG_MODULE_NAME i2c_thread
LOG_MODULE_REGISTER(LOG_MODULE_NAME);

const struct device *i2c_dev;
const static struct device *gpio_dev;
//static struct k_delayed_work read_eeprom;
#ifdef CONFIG_EXAMPLE_EXT_INT
K_SEM_DEFINE(sem_iic_op, 0, 1);
#endif

#define INT0_NODE DT_NODELABEL(button3)
#define INT0	DT_GPIO_LABEL(INT0_NODE, gpios)
#define INT0_PIN	DT_GPIO_PIN(INT0_NODE, gpios)
#define INT0_FLAGS	DT_GPIO_FLAGS(INT0_NODE, gpios)

static struct gpio_callback ext_int_cb_data;

#define EEPROM_SIM_SIZE                   (320u) //!< Simulated EEPROM size.

#define EEPROM_SIM_ADDR                   0x50    //!< Simulated EEPROM TWI slave address.

/* Slave memory addressing byte length */
#define EEPROM_SIM_ADDRESS_LEN_BYTES    2

#define IN_LINE_PRINT_CNT   (16u)   //!< Number of data bytes printed in a single line.


static int eeprom_read(uint16_t addr, uint8_t * pdata, size_t size)
{
    int ret;
    if (size > (EEPROM_SIM_SIZE))
    {
        return EINVAL;
    }
    do
    {
       uint16_t addr16 = addr;
       ret = i2c_write(i2c_dev, (uint8_t *)&addr16, EEPROM_SIM_ADDRESS_LEN_BYTES, EEPROM_SIM_ADDR);
       if (0 != ret)
       {
           break;
       }
       ret = i2c_read(i2c_dev, pdata, size, EEPROM_SIM_ADDR);
    }while (0);
    return ret;
}

static void eeprom_cmd_read(void)
{    
    uint8_t buf[IN_LINE_PRINT_CNT+1];

    for (uint16_t addr = 0; addr < EEPROM_SIM_SIZE; addr += IN_LINE_PRINT_CNT)
    {
        int err_code;
        err_code = eeprom_read(addr, buf, IN_LINE_PRINT_CNT);
        buf[IN_LINE_PRINT_CNT] = '\0';
        if (0 != err_code)
        {
            LOG_ERR("EEPROM transmission error %d\n", err_code);
            return;
        }

        LOG_HEXDUMP_INF(buf, IN_LINE_PRINT_CNT, "EEPROM: ");        
      
    }
}

// static void eeprom_read_fn(struct k_work *work)
// {
//     printk("eeprom read in system workqueue\n");
// 	eeprom_cmd_read();
//     k_delayed_work_submit(&read_eeprom, K_SECONDS(2));
// }

#ifdef CONFIG_EXAMPLE_EXT_INT
void ext_int_isr(const struct device *dev, struct gpio_callback *cb,
		    uint32_t pins)
{
	LOG_INF("external interrupt occurs at %x", pins);   
    k_sem_give(&sem_iic_op);    
}

void config_io_interrupt(void)
{
	int ret;

	gpio_dev = device_get_binding(INT0);
	if (!gpio_dev) {
		LOG_ERR("INT0 dev null");		
	}

	ret = gpio_pin_configure(gpio_dev, INT0_PIN, (GPIO_INPUT | GPIO_PULL_UP));
	if (ret != 0) {
		LOG_ERR("Error %d: failed to configure pin %d",
		       ret, INT0_PIN);		
	}

	ret = gpio_pin_interrupt_configure(gpio_dev,
					   INT0_PIN,
					   GPIO_INT_EDGE_FALLING);	                       
	if (ret != 0) {
		LOG_ERR("Error %d: failed to configure interrupt on pin %d",
			ret, INT0_PIN);		
	}

	gpio_init_callback(&ext_int_cb_data, ext_int_isr, BIT(INT0_PIN));
	gpio_add_callback(gpio_dev, &ext_int_cb_data);
	LOG_INF("External interrupt example at Pin:%d", INT0_PIN);
}
#endif //CONFIG_EXAMPLE_EXT_INT

void iic_thread(void)
{	
	
	LOG_INF("** I2C master example **");
	LOG_INF("This example is ported from nRF5_SDK\\examples\\peripheral\\twi_master_with_twis_slave");
	LOG_INF("The related twis example is from nRF5_SDK\\examples\\peripheral\\twi_master_with_twis_slave");	
	
	i2c_dev = device_get_binding(DT_LABEL(DT_NODELABEL(my_i2c)));
	if (!i2c_dev) {
		LOG_ERR("I2C Device driver not found");
		return;
	}
    uint32_t i2c_cfg = I2C_SPEED_SET(I2C_SPEED_FAST) | I2C_MODE_MASTER;
    if (i2c_configure(i2c_dev, i2c_cfg)) {
        LOG_ERR("I2C config failed");
        return;
    }
#ifdef CONFIG_EXAMPLE_EXT_INT
    config_io_interrupt();    
#endif
    
	// k_delayed_work_init(&read_eeprom, eeprom_read_fn);
    // k_delayed_work_submit(&read_eeprom, K_MSEC(50));	    

	while (1) {
#ifdef CONFIG_EXAMPLE_EXT_INT        
        k_sem_take(&sem_iic_op, K_FOREVER);
#endif                
        LOG_INF("i2c master thread");
        eeprom_cmd_read();
        k_sleep(K_SECONDS(2));
	}
}

K_THREAD_DEFINE(iic_thread_id, 1024, iic_thread, NULL, NULL,
		NULL, 7, 0, 0);
```

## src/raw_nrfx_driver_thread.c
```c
/*
 * Copyright (c) 2020 Nordic Semiconductor ASA
 *
 * SPDX-License-Identifier: LicenseRef-BSD-5-Clause-Nordic
 */

#include <zephyr.h>
#include <logging/log.h>
#include <nrfx_spim.h>
#include <nrfx_rtc.h>

#define LOG_MODULE_NAME raw_nrfx_thread
LOG_MODULE_REGISTER(LOG_MODULE_NAME);

#define SPI_SS_PIN 44
#define SPI_MOSI_PIN 0x2d
#define SPI_MISO_PIN 0x2e
#define SPI_SCK_PIN 0x2f

static const nrfx_spim_t spi = NRFX_SPIM_INSTANCE(3);
extern struct k_sem sem_raw_nrfx_txrx;
K_SEM_DEFINE(sem_raw_spi_sync, 0, 1);
#define TEST_STRING "Nordic"
static uint8_t       m_tx_buf[] = TEST_STRING;           /**< TX buffer. */
static uint8_t       m_rx_buf[sizeof(TEST_STRING) + 1];    /**< RX buffer. */
static const uint8_t m_length = sizeof(m_tx_buf);        /**< Transfer length. */

static const nrfx_rtc_t rtc = NRFX_RTC_INSTANCE(0);
#define LED1 29
#define COMPARE_COUNTERTIME  (5UL)   

/**
 * @brief SPI user event handler.
 * @param event
 */
void spi_event_handler(nrfx_spim_evt_t const * p_event,
                       void *                    p_context)
{
    k_sem_give(&sem_raw_spi_sync);	
    LOG_INF("Transfer completed.");
    if (m_rx_buf[0] != 0)
    {        
        LOG_HEXDUMP_INF(m_rx_buf, strlen((const char *)m_rx_buf), "Received: ");
    }
}

static int spi_data_exchange(void)
{

	// Reset rx buffer
	memset(m_rx_buf, 0, m_length);

	nrfx_spim_xfer_desc_t const spim_xfer_desc =
	{
		.p_tx_buffer = m_tx_buf,
		.tx_length   = m_length,
		.p_rx_buffer = m_rx_buf,
		.rx_length   = m_length,
	};
	int ret = nrfx_spim_xfer(&spi, &spim_xfer_desc, 0);	
	if (ret != NRFX_SUCCESS)
	{
		LOG_ERR("raw spi xfer err %d", ret);
		return ret;
	}

	k_sem_take(&sem_raw_spi_sync, K_FOREVER);

	return 0;

}

static void raw_spi_init(void)
{
	nrfx_err_t rc;
	
	//use Zephyr's method to setup ISR
	IRQ_CONNECT(NRFX_IRQ_NUMBER_GET(NRF_SPIM3), 1,
		    nrfx_isr, nrfx_spim_3_irq_handler, 0);

    nrfx_spim_config_t spi_config = 
	{
		.sck_pin        = SPI_SCK_PIN,                \
		.mosi_pin       = SPI_MOSI_PIN,                \
		.miso_pin       = SPI_MISO_PIN,                \
		.ss_pin         = SPI_SS_PIN,                \
		.ss_active_high = false,                                 \
		.irq_priority   = NRFX_SPIM_DEFAULT_CONFIG_IRQ_PRIORITY, \
		.orc            = 0xFF,                                  \
		.frequency      = NRF_SPIM_FREQ_4M,                      \
		.mode           = NRF_SPIM_MODE_0,                       \
		.bit_order      = NRF_SPIM_BIT_ORDER_MSB_FIRST,          \		
	};

    rc = nrfx_spim_init(&spi, &spi_config, spi_event_handler, NULL);
	if (rc != NRFX_SUCCESS)
	{
		LOG_ERR("raw spi init err %d", rc);
	}
	
}

static void rtc_handler(nrfx_rtc_int_type_t int_type)
{
    if (int_type == NRFX_RTC_INT_COMPARE0)
    {
		LOG_INF("raw RTC cc0 evt");
        nrf_gpio_pin_toggle(LED1);
    }
}

static void raw_rtc_init(void)
{
	nrfx_err_t rc;
	
	LOG_INF("*** Raw RTC usage example ***");
	//use Zephyr's method to setup ISR
	IRQ_CONNECT(NRFX_IRQ_NUMBER_GET(NRF_RTC0), 1,
		    nrfx_isr, nrfx_rtc_0_irq_handler, 0);

    //Initialize RTC instance
    nrfx_rtc_config_t config = NRFX_RTC_DEFAULT_CONFIG;
    config.prescaler = 4095;
    rc = nrfx_rtc_init(&rtc, &config, rtc_handler);
	if (rc != NRFX_SUCCESS)
	{
		LOG_ERR("raw rtc init err %d", rc);
	}    


    //Set compare channel to trigger interrupt after COMPARE_COUNTERTIME seconds
    rc = nrfx_rtc_cc_set(&rtc, 0, COMPARE_COUNTERTIME * 8, true);
	if (rc != NRFX_SUCCESS)
	{
		LOG_ERR("nrfx_rtc_cc_set err %d", rc);
	}

	
    //Power on RTC instance
    nrfx_rtc_enable(&rtc);

	nrf_gpio_pin_clear(LED1);
	nrf_gpio_cfg_output(LED1);
	
}

void raw_nrfx_thread(void)
{	
	
	LOG_INF("**Raw SPIM example working with nRF5_SDK\\examples\\peripheral\\spis directly");	
	LOG_WRN("### make sure CONFIG_SPI is not set; otherwise it would have conflicts ###");
	raw_spi_init();
	raw_rtc_init();
    k_sem_take(&sem_raw_nrfx_txrx, K_FOREVER);
	while (1) {                
        LOG_INF("raw spi master thread");
        spi_data_exchange();
        k_sleep(K_MSEC(200)); 
	}
}

K_THREAD_DEFINE(raw_nrfx_thread_id, 1024, raw_nrfx_thread, NULL, NULL,
		NULL, 7, 0, 0);
```

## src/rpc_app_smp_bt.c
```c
/*
 * Copyright (c) 2020 Nordic Semiconductor ASA
 *
 * SPDX-License-Identifier: LicenseRef-BSD-5-Clause-Nordic
 */
#include <errno.h>
#include <init.h>
#include <tinycbor/cbor.h>
#include <nrf_rpc_cbor.h>
#include "../../common_ids.h"
#include <mgmt/mcumgr/buf.h>
#include <mgmt/mcumgr/smp.h>
#include <net/buf.h>
#include <logging/log.h>

LOG_MODULE_REGISTER(rpc_app_smp, 2);

#define CBOR_BUF_SIZE 16
static struct zephyr_smp_transport smp_rpc_transport;

NRF_RPC_GROUP_DEFINE(rpc_smp, "rpc_smp", NULL, NULL, NULL);

static void rsp_error_code_send(int err_code)
{
	struct nrf_rpc_cbor_ctx ctx;

	NRF_RPC_CBOR_ALLOC(ctx, CBOR_BUF_SIZE);

	cbor_encode_int(&ctx.encoder, err_code);

	nrf_rpc_cbor_rsp_no_err(&ctx);
}

static int smp_receive_data(const void *buf, uint16_t len)
{
	struct net_buf *nb;

	LOG_HEXDUMP_INF(buf, len, "rpc app smp rx:");
	nb = mcumgr_buf_alloc();
	if (!nb)
	{
		LOG_ERR("net buf alloc failed");
		return -ENOMEM;
	}
	net_buf_add_mem(nb, buf, len);
	zephyr_smp_rx_req(&smp_rpc_transport, nb);	

	return len;
}

static void rpc_app_bt_smp_receive_cb(CborValue *value, void *handler_data)
{	
	CborError cbor_err;
	int err;
	size_t length;
	uint8_t buf[270];

	LOG_INF("rpc rx data");
	err = 0;
	length = sizeof(buf);
	cbor_err = cbor_value_copy_byte_string(value, buf, &length, NULL);

	if (cbor_err != CborNoError || length < 0 || length > sizeof(buf)) {
		err = -NRF_EBADMSG;
		LOG_ERR("cbor copy err in smp rx");		
	}
	else
	{		
		err = smp_receive_data(buf, length);
	}

	nrf_rpc_cbor_decoding_done(value);

	rsp_error_code_send(err);
}

NRF_RPC_CBOR_CMD_DECODER(rpc_smp, rpc_app_bt_smp_receive,
			 RPC_COMMAND_NET_BT_SMP_RECEIVE_CB,
			 rpc_app_bt_smp_receive_cb, NULL);

/*

static uint16_t m_rpc_mtu = 23;

static uint16_t smp_rpc_get_mtu(const struct net_buf *nb)
{
	return m_rpc_mtu;
}

static void rpc_app_bt_mtu_size_cb(CborValue *value, void *handler_data)
{	
	CborError cbor_err;
	int err;
	uint16_t mtu;

	err = 0;
	cbor_err = cbor_value_get_int(value, &mtu);
	if (cbor_err != CborNoError) {
		err = -NRF_EBADMSG;
	}

	m_rpc_mtu = mtu;

	nrf_rpc_cbor_decoding_done(value);

	rsp_error_code_send(err);
}

NRF_RPC_CBOR_CMD_DECODER(rpc_smp, rpc_app_bt_mtu_size,
			 RPC_COMMAND_NET_BT_MTU_SIZE_CB,
			 rpc_app_bt_mtu_size_cb, NULL);

*/

static void rsp_error_code_handle(CborValue *value, void *handler_data)
{
	CborError cbor_err;

	if (!cbor_value_is_integer(value)) {
		*(int *)handler_data = -NRF_EINVAL;
	}

	cbor_err = cbor_value_get_int(value, (int *)handler_data);
	if (cbor_err != CborNoError) {
		*(int *)handler_data = -NRF_EINVAL;
	}
}

int rpc_app_bt_smp_send(uint8_t *buffer, uint16_t length)
{
	int err;
	int result;
	struct nrf_rpc_cbor_ctx ctx;

	if (!buffer || length < 1) {
		LOG_ERR("rpc app send err");
		return -NRF_EINVAL;
	}	

	NRF_RPC_CBOR_ALLOC(ctx, CBOR_BUF_SIZE + length);
	
	cbor_encode_byte_string(&ctx.encoder, buffer, length);	

	err = nrf_rpc_cbor_cmd(&rpc_smp, RPC_COMMAND_APP_BT_SMP_SEND, &ctx,
			       rsp_error_code_handle, &result);
	if (err < 0) {
		return err;
	}

	return result;
}
/**
 * Transmits the specified SMP response.
 */
static int smp_rpc_tx_pkt(struct zephyr_smp_transport *zst, struct net_buf *nb)
{	
	int rc;
	LOG_HEXDUMP_INF(nb->data, nb->len, "rpc app send");
	rc = rpc_app_bt_smp_send(nb->data, nb->len);
	mcumgr_buf_free(nb);
	return rc;
}

int rpc_app_bt_smp_get_mtu(void)
{
	int err;
	int result;
	struct nrf_rpc_cbor_ctx ctx;

	NRF_RPC_CBOR_ALLOC(ctx, CBOR_BUF_SIZE);

	err = nrf_rpc_cbor_cmd(&rpc_smp, RPC_COMMAND_APP_BT_SMP_GET_MTU, &ctx,
			       rsp_error_code_handle, &result);
	if (err < 0) {
		return err;
	}

	return result;
}

static uint16_t smp_rpc_get_mtu(const struct net_buf *nb)
{
	int mtu = rpc_app_bt_smp_get_mtu();
	return mtu < 0 ? 0: mtu;     
}

int smp_rpc_init(const struct device *dev)
{	
	ARG_UNUSED(dev);
	
	zephyr_smp_transport_init(&smp_rpc_transport, smp_rpc_tx_pkt,
				  smp_rpc_get_mtu, NULL,
				  NULL);
	return 0;
}

SYS_INIT(smp_rpc_init, APPLICATION, CONFIG_APPLICATION_INIT_PRIORITY);
```

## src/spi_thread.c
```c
/*
 * Copyright (c) 2020 Nordic Semiconductor ASA
 *
 * SPDX-License-Identifier: LicenseRef-BSD-5-Clause-Nordic
 */

#include <zephyr.h>
#include <device.h>
#include <devicetree.h>
#include <drivers/gpio.h>
#include <logging/log.h>
#include <drivers/spi.h>

#define LOG_MODULE_NAME spi_thread
LOG_MODULE_REGISTER(LOG_MODULE_NAME);

#define DELAY_SPI_CS_ACTIVE_US 2
#define TEST_STRING "Nordic"

const struct device *spi_dev;
extern struct k_sem sem_spi_txrx;

static int spi_data_exchange(void)
{
    int err;
    struct spi_cs_control cs_ctrl;
    struct spi_config spi_cfg = {0};

	spi_cfg.frequency = 8000000U;
	spi_cfg.operation = SPI_WORD_SET(8);

	cs_ctrl.gpio_dev = device_get_binding(DT_GPIO_LABEL(DT_NODELABEL(my_spi), cs_gpios));
	if (!cs_ctrl.gpio_dev) {
        LOG_ERR("cannot find CS GPIO device");
		return -ENODEV;
	}

	cs_ctrl.gpio_pin = DT_GPIO_PIN(DT_NODELABEL(my_spi), cs_gpios);
	cs_ctrl.gpio_dt_flags = DT_GPIO_FLAGS(DT_NODELABEL(my_spi), cs_gpios);

	cs_ctrl.delay = DELAY_SPI_CS_ACTIVE_US;

	spi_cfg.cs = &cs_ctrl;

	uint8_t buf[] = TEST_STRING;
    uint8_t data[] = TEST_STRING;

	struct spi_buf spi_buf[2] = {
		{
			.buf = buf,
			.len = sizeof(buf),
		},
		{
			.buf = data,
			.len = sizeof(data)
		}
	};
    
	const struct spi_buf_set tx_set = {
		.buffers = spi_buf,
		.count = 1
	};

	const struct spi_buf_set rx_set = {
		.buffers = spi_buf,
		.count = 1
	};

	// const struct spi_buf_set tx_set = {
	// 	.buffers = spi_buf,
	// 	.count = 2
	// };

	// const struct spi_buf_set rx_set = {
	// 	.buffers = spi_buf,
	// 	.count = 2
	// };    

	err = spi_transceive(spi_dev, &spi_cfg, &tx_set, &rx_set);
    
    if (err)
    {
        LOG_ERR("SPI transcation failed err %d", err);
    }
    else
    {
        LOG_HEXDUMP_INF(rx_set.buffers->buf, rx_set.buffers->len, "Received SPI data: ");
    }

    return err;

}

void spi_thread(void)
{	
	
	LOG_INF("** SPI master example **");
	LOG_INF("This example is ported from nRF5_SDK\\examples\\peripheral\\spi");
	LOG_INF("The related spis example is from nRF5_SDK\\examples\\peripheral\\spis");
	
	spi_dev = device_get_binding(DT_LABEL(DT_NODELABEL(my_spi)));
	if (!spi_dev) {
		LOG_ERR("SPIM driver not found.\n");
		return;
	}
    k_sem_take(&sem_spi_txrx, K_FOREVER);
	while (1) {                
        LOG_INF("spi master thread");
        spi_data_exchange();
        k_sleep(K_MSEC(800)); 
	}
}

K_THREAD_DEFINE(spi_thread_id, 1024, spi_thread, NULL, NULL,
		NULL, 7, 0, 0);
```
